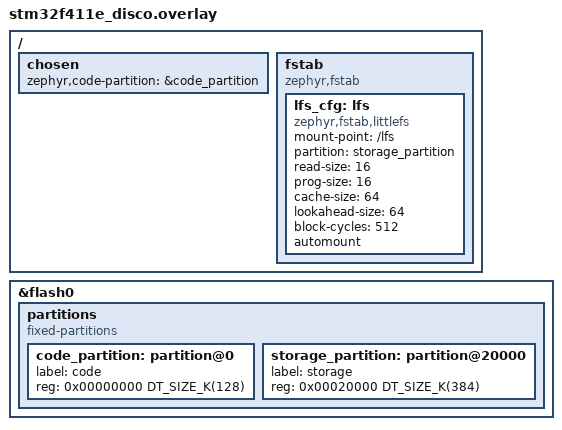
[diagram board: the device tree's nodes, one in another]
/ {
    chosen {
        zephyr,code-partition = &code_partition;
    };

    fstab {
        compatible = "zephyr,fstab";

        lfs_cfg: lfs {
            compatible = "zephyr,fstab,littlefs";
            mount-point = "/lfs";
            partition = <&storage_partition>;
            read-size = <16>;
            prog-size = <16>;
            cache-size = <64>;
            lookahead-size = <64>;
            block-cycles = <512>;
            automount;
        };
    };

};

&flash0 {
    partitions {
        compatible = "fixed-partitions";
        #address-cells = <1>;
        #size-cells = <1>;

        code_partition: partition@0 {
            label = "code";
            reg = <0x00000000 DT_SIZE_K(128)>;
        };

        storage_partition: partition@20000 {
            label = "storage";
            reg = <0x00020000 DT_SIZE_K(384)>;
        };
    };
};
